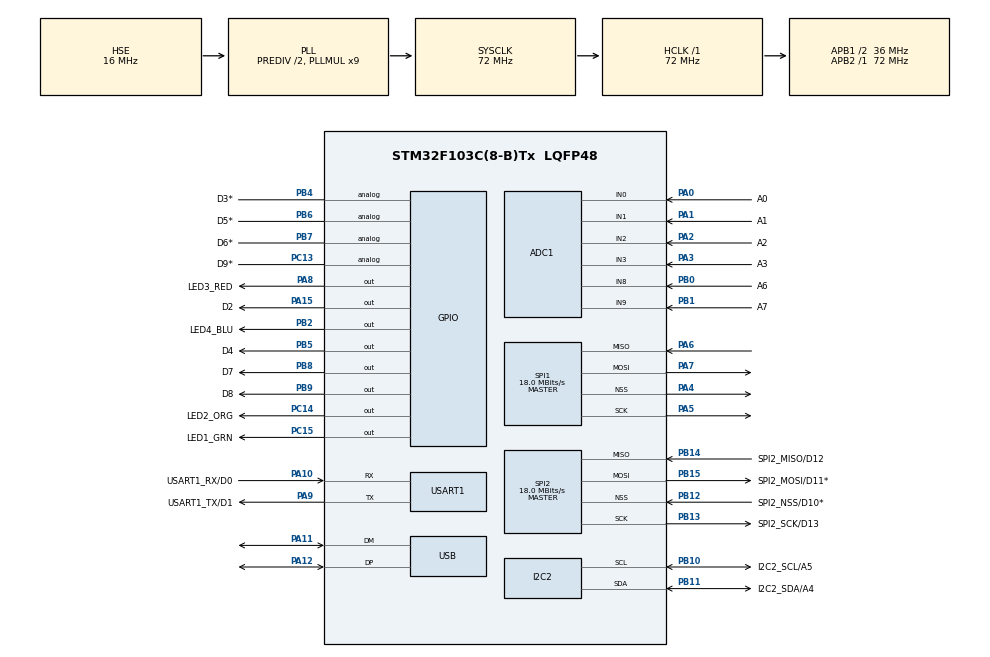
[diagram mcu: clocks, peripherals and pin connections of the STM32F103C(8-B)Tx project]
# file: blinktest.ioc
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ADC1.Channel-3\#ChannelRegularConversion=ADC_CHANNEL_0
ADC1.NbrOfConversionFlag=1
ADC1.Rank-3\#ChannelRegularConversion=1
ADC1.SamplingTime-3\#ChannelRegularConversion=ADC_SAMPLETIME_1CYCLE_5
ADC1.master=1
Mcu.Family=STM32F1
Mcu.Name=STM32F103C(8-B)Tx
Mcu.Package=LQFP48
NVIC.PriorityGroup=NVIC_PRIORITYGROUP_4
PA0-WKUP.GPIO_Label=A0
PA0-WKUP.Signal=ADCx_IN0
PA1.GPIO_Label=A1
PA1.Signal=ADCx_IN1
PA10.GPIO_Label=USART1_RX/D0
PA10.Mode=Asynchronous
PA10.Signal=USART1_RX
PA11.Mode=Device
PA11.Signal=USB_DM
PA12.Mode=Device
PA12.Signal=USB_DP
PA13.Mode=Trace_Asynchronous_SW
PA13.Signal=SYS_JTMS-SWDIO
PA14.Mode=Trace_Asynchronous_SW
PA14.Signal=SYS_JTCK-SWCLK
PA15.GPIO_Label=D2
PA15.Signal=GPIO_Output
PA2.GPIO_Label=A2
PA2.Signal=ADCx_IN2
PA3.GPIO_Label=A3
PA3.Signal=ADCx_IN3
PA4.Mode=NSS_Signal_Hard_Output
PA4.Signal=SPI1_NSS
PA5.Mode=Full_Duplex_Master
PA5.Signal=SPI1_SCK
PA6.Mode=Full_Duplex_Master
PA6.Signal=SPI1_MISO
PA7.Mode=Full_Duplex_Master
PA7.Signal=SPI1_MOSI
PA8.GPIO_Label=LED3_RED
PA8.Signal=GPIO_Output
PA9.GPIO_Label=USART1_TX/D1
PA9.Mode=Asynchronous
PA9.Signal=USART1_TX
PB0.GPIO_Label=A6
PB0.Signal=ADCx_IN8
PB1.GPIO_Label=A7
PB1.Signal=ADCx_IN9
PB10.GPIO_Label=I2C2_SCL/A5
PB10.Mode=I2C
PB10.Signal=I2C2_SCL
PB11.GPIO_Label=I2C2_SDA/A4
PB11.Mode=I2C
PB11.Signal=I2C2_SDA
PB12.GPIO_Label=SPI2_NSS/D10*
PB12.Mode=NSS_Signal_Hard_Input
PB12.Signal=SPI2_NSS
PB13.GPIO_Label=SPI2_SCK/D13
PB13.Mode=Full_Duplex_Master
PB13.Signal=SPI2_SCK
PB14.GPIO_Label=SPI2_MISO/D12
PB14.Mode=Full_Duplex_Master
PB14.Signal=SPI2_MISO
PB15.GPIO_Label=SPI2_MOSI/D11*
PB15.Mode=Full_Duplex_Master
PB15.Signal=SPI2_MOSI
PB2.GPIO_Label=LED4_BLU
PB2.Signal=GPIO_Output
PB3.Mode=Trace_Asynchronous_SW
PB3.Signal=SYS_JTDO-TRACESWO
PB4.GPIO_Label=D3*
PB4.Signal=GPIO_Analog
PB5.GPIO_Label=D4
PB5.Signal=GPIO_Output
PB6.GPIO_Label=D5*
PB6.Signal=GPIO_Analog
PB7.GPIO_Label=D6*
PB7.Signal=GPIO_Analog
PB8.GPIO_Label=D7
PB8.Signal=GPIO_Output
PB9.GPIO_Label=D8
PB9.Signal=GPIO_Output
PC13-TAMPER-RTC.GPIO_Label=D9*
PC13-TAMPER-RTC.Signal=GPIO_Analog
PC14-OSC32_IN.GPIO_Label=LED2_ORG
PC14-OSC32_IN.Signal=GPIO_Output
PC15-OSC32_OUT.GPIO_Label=LED1_GRN
PC15-OSC32_OUT.Signal=GPIO_Output
PD0-OSC_IN.Mode=HSE-External-Oscillator
PD0-OSC_IN.Signal=RCC_OSC_IN
PD1-OSC_OUT.Mode=HSE-External-Oscillator
PD1-OSC_OUT.Signal=RCC_OSC_OUT
ProjectManager.HeapSize=0x200
ProjectManager.StackSize=0x400
ProjectManager.TargetToolchain=STM32CubeIDE
RCC.ADCPresc=RCC_ADCPCLK2_DIV6
RCC.AHBFreq_Value=72000000
RCC.APB1CLKDivider=RCC_HCLK_DIV2
RCC.APB1Freq_Value=36000000
RCC.APB1TimFreq_Value=72000000
RCC.APB2Freq_Value=72000000
RCC.APB2TimFreq_Value=72000000
RCC.HCLKFreq_Value=72000000
RCC.HSEDivPLL=RCC_HSE_PREDIV_DIV2
RCC.HSE_VALUE=16000000
RCC.PLLMUL=RCC_PLL_MUL9
RCC.PLLSourceVirtual=RCC_PLLSOURCE_HSE
RCC.SYSCLKFreq_VALUE=72000000
RCC.SYSCLKSource=RCC_SYSCLKSOURCE_PLLCLK
RCC.USBFreq_Value=48000000
RCC.USBPrescaler=RCC_USBCLKSOURCE_PLL_DIV1_5
SH.ADCx_IN0.0=ADC1_IN0,IN0
SH.ADCx_IN1.0=ADC1_IN1,IN1
SH.ADCx_IN2.0=ADC1_IN2,IN2
SH.ADCx_IN3.0=ADC1_IN3,IN3
SH.ADCx_IN8.0=ADC1_IN8,IN8
SH.ADCx_IN9.0=ADC1_IN9,IN9
SPI1.BaudRatePrescaler=SPI_BAUDRATEPRESCALER_4
SPI1.CalculateBaudRate=18.0 MBits/s
SPI1.Direction=SPI_DIRECTION_2LINES
SPI1.Mode=SPI_MODE_MASTER
SPI1.VirtualNSS=VM_NSSHARD
SPI1.VirtualType=VM_MASTER
SPI2.CalculateBaudRate=18.0 MBits/s
SPI2.Direction=SPI_DIRECTION_2LINES
SPI2.Mode=SPI_MODE_MASTER
SPI2.VirtualNSS=VM_NSSHARD
SPI2.VirtualType=VM_MASTER
USART1.VirtualMode=VM_ASYNC
VP_ADC1_TempSens_Input.Mode=IN-TempSens
VP_ADC1_Vref_Input.Mode=IN-Vrefint
board=custom

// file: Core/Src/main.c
/* USER CODE BEGIN Header */
/**
  ******************************************************************************
  * @file           : main.c
  * @brief          : Main program body
  ******************************************************************************
  * @attention
  *
  * Copyright (c) 2023 STMicroelectronics.
  * All rights reserved.
  *
  * This software is licensed under terms that can be found in the LICENSE file
  * in the root directory of this software component.
  * If no LICENSE file comes with this software, it is provided AS-IS.
  *
  ******************************************************************************
  */
/* USER CODE END Header */
#include "main.h"
#include "adc.h"
#include "i2c.h"
#include "spi.h"
#include "usart.h"
#include "usb.h"
#include "gpio.h"

void SystemClock_Config(void);

int main(void)
{

  /* MCU Configuration--------------------------------------------------------*/

  /* Reset of all peripherals, Initializes the Flash interface and the Systick. */
  HAL_Init();

  /* Configure the system clock */
  SystemClock_Config();

  /* Initialize all configured peripherals */
  MX_GPIO_Init();
  MX_ADC1_Init();
  MX_SPI2_Init();
  MX_USART1_UART_Init();
  MX_USB_PCD_Init();
  MX_SPI1_Init();
  MX_I2C2_Init();
  /* USER CODE BEGIN 2 */

  HAL_GPIO_WritePin(LED1_GRN_GPIO_Port, LED1_GRN_Pin, GPIO_PIN_SET);
  HAL_GPIO_WritePin(LED2_ORG_GPIO_Port, LED2_ORG_Pin, GPIO_PIN_SET);
  HAL_GPIO_WritePin(LED3_RED_GPIO_Port, LED3_RED_Pin, GPIO_PIN_SET);
  HAL_GPIO_WritePin(LED4_BLU_GPIO_Port, LED4_BLU_Pin, GPIO_PIN_SET);
  uint32_t tick1 = 0;
  uint8_t ledPattern = 0;

  /* USER CODE END 2 */

  /* Infinite loop */
  /* USER CODE BEGIN WHILE */
  while (1)
  {
    if(HAL_GetTick() - tick1 >= 150) {
      tick1 = HAL_GetTick();
      ledPattern++;
      if((ledPattern >> 4) > 0) ledPattern=0;

      HAL_GPIO_WritePin(LED3_RED_GPIO_Port, LED3_RED_Pin, (ledPattern & 1) ? GPIO_PIN_RESET : GPIO_PIN_SET);
      HAL_GPIO_WritePin(LED2_ORG_GPIO_Port, LED2_ORG_Pin, (ledPattern & 2) ? GPIO_PIN_RESET : GPIO_PIN_SET);
      HAL_GPIO_WritePin(LED1_GRN_GPIO_Port, LED1_GRN_Pin, (ledPattern & 4) ? GPIO_PIN_RESET : GPIO_PIN_SET);
      HAL_GPIO_WritePin(LED4_BLU_GPIO_Port, LED4_BLU_Pin, (ledPattern & 8) ? GPIO_PIN_RESET : GPIO_PIN_SET);
    }
    /* USER CODE END WHILE */

  }
}

void SystemClock_Config(void)
{
  RCC_OscInitTypeDef RCC_OscInitStruct = {0};
  RCC_ClkInitTypeDef RCC_ClkInitStruct = {0};
  RCC_PeriphCLKInitTypeDef PeriphClkInit = {0};

  /** Initializes the RCC Oscillators according to the specified parameters
  * in the RCC_OscInitTypeDef structure.
  */
  RCC_OscInitStruct.OscillatorType = RCC_OSCILLATORTYPE_HSE;
  RCC_OscInitStruct.HSEState = RCC_HSE_ON;
  RCC_OscInitStruct.HSEPredivValue = RCC_HSE_PREDIV_DIV2;
  RCC_OscInitStruct.HSIState = RCC_HSI_ON;
  RCC_OscInitStruct.PLL.PLLState = RCC_PLL_ON;
  RCC_OscInitStruct.PLL.PLLSource = RCC_PLLSOURCE_HSE;
  RCC_OscInitStruct.PLL.PLLMUL = RCC_PLL_MUL9;
  if (HAL_RCC_OscConfig(&RCC_OscInitStruct) != HAL_OK)
  {
    Error_Handler();
  }

  /** Initializes the CPU, AHB and APB buses clocks
  */
  RCC_ClkInitStruct.ClockType = RCC_CLOCKTYPE_HCLK|RCC_CLOCKTYPE_SYSCLK
                              |RCC_CLOCKTYPE_PCLK1|RCC_CLOCKTYPE_PCLK2;
  RCC_ClkInitStruct.SYSCLKSource = RCC_SYSCLKSOURCE_PLLCLK;
  RCC_ClkInitStruct.AHBCLKDivider = RCC_SYSCLK_DIV1;
  RCC_ClkInitStruct.APB1CLKDivider = RCC_HCLK_DIV2;
  RCC_ClkInitStruct.APB2CLKDivider = RCC_HCLK_DIV1;

  if (HAL_RCC_ClockConfig(&RCC_ClkInitStruct, FLASH_LATENCY_2) != HAL_OK)
  {
    Error_Handler();
  }
  PeriphClkInit.PeriphClockSelection = RCC_PERIPHCLK_ADC|RCC_PERIPHCLK_USB;
  PeriphClkInit.AdcClockSelection = RCC_ADCPCLK2_DIV6;
  PeriphClkInit.UsbClockSelection = RCC_USBCLKSOURCE_PLL_DIV1_5;
  if (HAL_RCCEx_PeriphCLKConfig(&PeriphClkInit) != HAL_OK)
  {
    Error_Handler();
  }
}

void Error_Handler(void)
{
  __disable_irq();
  while (1)
  {
  }
}
